# HC32F448 register map
File version: 1.0
CPU: CM4 r0p1, little endian, MPU, FPU, 4 interrupt priority bits
Registers are 32-bit, read-write, reset 0x0 unless marked. A register's access mark holds for its fields unless they carry their own. Offsets are from the block's base; [hi:lo] are bit positions; {n}, {i} and the like mark numbered series.

## TMR41
Base 0x40038000
0x00 OCCRUH 16-bit
0x04 OCCRUL 16-bit
0x08 OCCRVH 16-bit
0x0C OCCRVL 16-bit
0x10 OCCRWH 16-bit
0x14 OCCRWL 16-bit
0x18 OCCRXH 16-bit
0x1C OCCRXL 16-bit
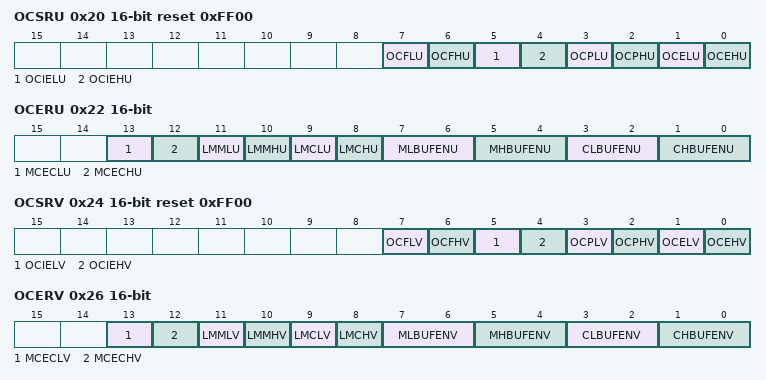
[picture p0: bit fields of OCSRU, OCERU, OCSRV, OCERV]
0x20 OCSRU 16-bit reset 0xFF00
  [7] OCFLU, [6] OCFHU, [5] OCIELU, [4] OCIEHU, [3] OCPLU, [2] OCPHU, [1] OCELU, [0] OCEHU
0x22 OCERU 16-bit
  [13] MCECLU, [12] MCECHU, [11] LMMLU, [10] LMMHU, [9] LMCLU, [8] LMCHU, [7:6] MLBUFENU, [5:4] MHBUFENU, [3:2] CLBUFENU, [1:0] CHBUFENU
0x24 OCSRV 16-bit reset 0xFF00
  [7] OCFLV, [6] OCFHV, [5] OCIELV, [4] OCIEHV, [3] OCPLV, [2] OCPHV, [1] OCELV, [0] OCEHV
0x26 OCERV 16-bit
  [13] MCECLV, [12] MCECHV, [11] LMMLV, [10] LMMHV, [9] LMCLV, [8] LMCHV, [7:6] MLBUFENV, [5:4] MHBUFENV, [3:2] CLBUFENV, [1:0] CHBUFENV
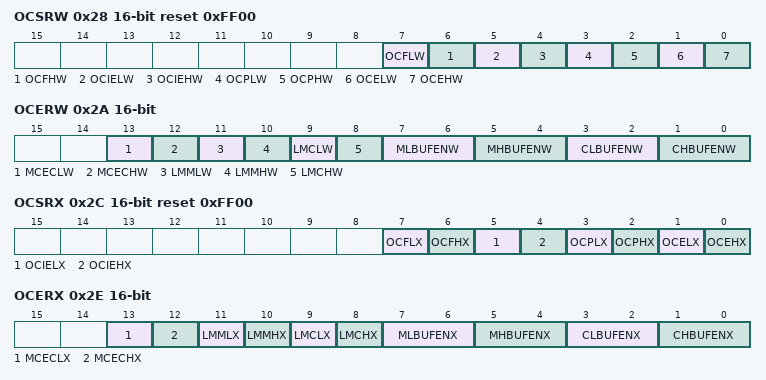
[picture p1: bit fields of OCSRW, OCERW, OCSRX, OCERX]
0x28 OCSRW 16-bit reset 0xFF00
  [7] OCFLW, [6] OCFHW, [5] OCIELW, [4] OCIEHW, [3] OCPLW, [2] OCPHW, [1] OCELW, [0] OCEHW
0x2A OCERW 16-bit
  [13] MCECLW, [12] MCECHW, [11] LMMLW, [10] LMMHW, [9] LMCLW, [8] LMCHW, [7:6] MLBUFENW, [5:4] MHBUFENW, [3:2] CLBUFENW, [1:0] CHBUFENW
0x2C OCSRX 16-bit reset 0xFF00
  [7] OCFLX, [6] OCFHX, [5] OCIELX, [4] OCIEHX, [3] OCPLX, [2] OCPHX, [1] OCELX, [0] OCEHX
0x2E OCERX 16-bit
  [13] MCECLX, [12] MCECHX, [11] LMMLX, [10] LMMHX, [9] LMCLX, [8] LMCHX, [7:6] MLBUFENX, [5:4] MHBUFENX, [3:2] CLBUFENX, [1:0] CHBUFENX
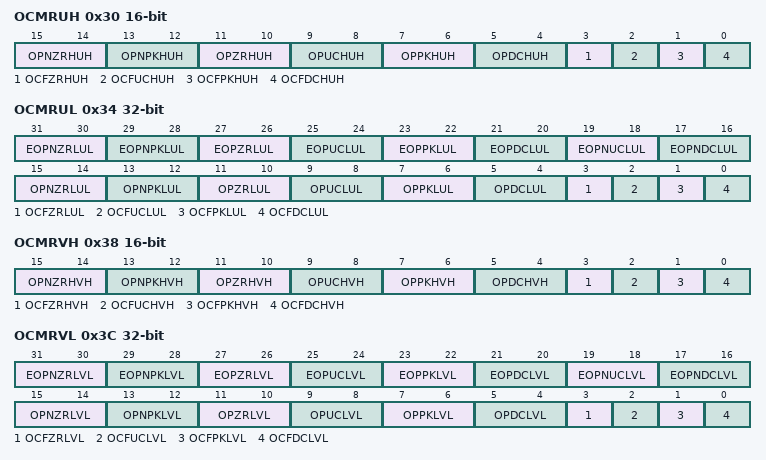
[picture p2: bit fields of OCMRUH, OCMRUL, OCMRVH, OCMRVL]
0x30 OCMRUH 16-bit
  [15:14] OPNZRHUH, [13:12] OPNPKHUH, [11:10] OPZRHUH, [9:8] OPUCHUH, [7:6] OPPKHUH, [5:4] OPDCHUH, [3] OCFZRHUH, [2] OCFUCHUH, [1] OCFPKHUH, [0] OCFDCHUH
0x34 OCMRUL
  [31:30] EOPNZRLUL, [29:28] EOPNPKLUL, [27:26] EOPZRLUL, [25:24] EOPUCLUL, [23:22] EOPPKLUL, [21:20] EOPDCLUL, [19:18] EOPNUCLUL, [17:16] EOPNDCLUL, [15:14] OPNZRLUL, [13:12] OPNPKLUL, [11:10] OPZRLUL, [9:8] OPUCLUL, [7:6] OPPKLUL, [5:4] OPDCLUL, [3] OCFZRLUL, [2] OCFUCLUL, [1] OCFPKLUL, [0] OCFDCLUL
0x38 OCMRVH 16-bit
  [15:14] OPNZRHVH, [13:12] OPNPKHVH, [11:10] OPZRHVH, [9:8] OPUCHVH, [7:6] OPPKHVH, [5:4] OPDCHVH, [3] OCFZRHVH, [2] OCFUCHVH, [1] OCFPKHVH, [0] OCFDCHVH
0x3C OCMRVL
  [31:30] EOPNZRLVL, [29:28] EOPNPKLVL, [27:26] EOPZRLVL, [25:24] EOPUCLVL, [23:22] EOPPKLVL, [21:20] EOPDCLVL, [19:18] EOPNUCLVL, [17:16] EOPNDCLVL, [15:14] OPNZRLVL, [13:12] OPNPKLVL, [11:10] OPZRLVL, [9:8] OPUCLVL, [7:6] OPPKLVL, [5:4] OPDCLVL, [3] OCFZRLVL, [2] OCFUCLVL, [1] OCFPKLVL, [0] OCFDCLVL
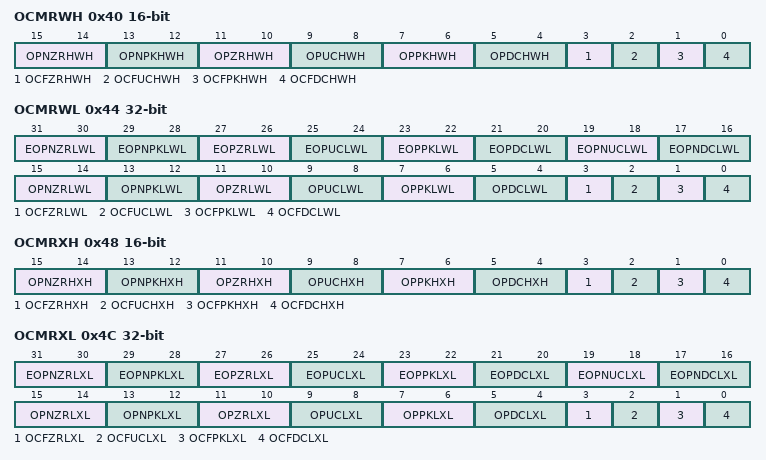
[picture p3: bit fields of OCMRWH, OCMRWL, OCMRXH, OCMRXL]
0x40 OCMRWH 16-bit
  [15:14] OPNZRHWH, [13:12] OPNPKHWH, [11:10] OPZRHWH, [9:8] OPUCHWH, [7:6] OPPKHWH, [5:4] OPDCHWH, [3] OCFZRHWH, [2] OCFUCHWH, [1] OCFPKHWH, [0] OCFDCHWH
0x44 OCMRWL
  [31:30] EOPNZRLWL, [29:28] EOPNPKLWL, [27:26] EOPZRLWL, [25:24] EOPUCLWL, [23:22] EOPPKLWL, [21:20] EOPDCLWL, [19:18] EOPNUCLWL, [17:16] EOPNDCLWL, [15:14] OPNZRLWL, [13:12] OPNPKLWL, [11:10] OPZRLWL, [9:8] OPUCLWL, [7:6] OPPKLWL, [5:4] OPDCLWL, [3] OCFZRLWL, [2] OCFUCLWL, [1] OCFPKLWL, [0] OCFDCLWL
0x48 OCMRXH 16-bit
  [15:14] OPNZRHXH, [13:12] OPNPKHXH, [11:10] OPZRHXH, [9:8] OPUCHXH, [7:6] OPPKHXH, [5:4] OPDCHXH, [3] OCFZRHXH, [2] OCFUCHXH, [1] OCFPKHXH, [0] OCFDCHXH
0x4C OCMRXL
  [31:30] EOPNZRLXL, [29:28] EOPNPKLXL, [27:26] EOPZRLXL, [25:24] EOPUCLXL, [23:22] EOPPKLXL, [21:20] EOPDCLXL, [19:18] EOPNUCLXL, [17:16] EOPNDCLXL, [15:14] OPNZRLXL, [13:12] OPNPKLXL, [11:10] OPZRLXL, [9:8] OPUCLXL, [7:6] OPPKLXL, [5:4] OPDCLXL, [3] OCFZRLXL, [2] OCFUCLXL, [1] OCFPKLXL, [0] OCFDCLXL
0x50 CPSR 16-bit reset 0xFFFF
0x54 CNTR 16-bit
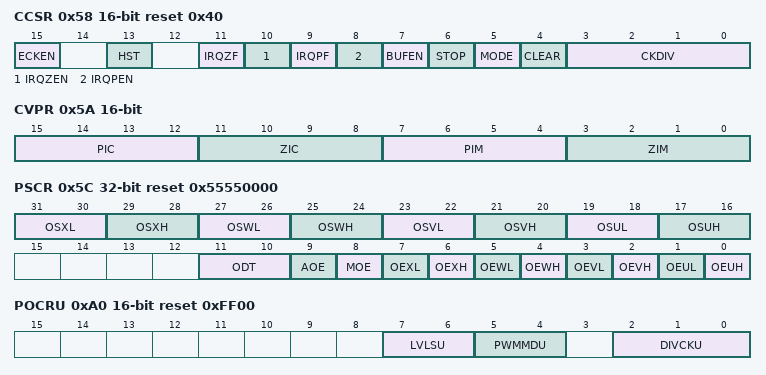
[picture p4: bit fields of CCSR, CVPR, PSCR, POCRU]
0x58 CCSR 16-bit reset 0x40
  [15] ECKEN, [13] HST, [11] IRQZF, [10] IRQZEN, [9] IRQPF, [8] IRQPEN, [7] BUFEN, [6] STOP, [5] MODE, [4] CLEAR, [3:0] CKDIV
0x5A CVPR 16-bit
  [15:12] PIC ro, [11:8] ZIC ro, [7:4] PIM, [3:0] ZIM
0x5C PSCR reset 0x55550000
  [31:30] OSXL, [29:28] OSXH, [27:26] OSWL, [25:24] OSWH, [23:22] OSVL, [21:20] OSVH, [19:18] OSUL, [17:16] OSUH, [11:10] ODT, [9] AOE, [8] MOE, [7] OEXL, [6] OEXH, [5] OEWL, [4] OEWH, [3] OEVL, [2] OEVH, [1] OEUL, [0] OEUH
0x82 PFSRU 16-bit
0x84 PDARU 16-bit
0x86 PDBRU 16-bit
0x8A PFSRV 16-bit
0x8C PDARV 16-bit
0x8E PDBRV 16-bit
0x92 PFSRW 16-bit
0x94 PDARW 16-bit
0x96 PDBRW 16-bit
0x9A PFSRX 16-bit
0x9C PDARX 16-bit
0x9E PDBRX 16-bit
0xA0 POCRU 16-bit reset 0xFF00
  [7:6] LVLSU, [5:4] PWMMDU, [2:0] DIVCKU
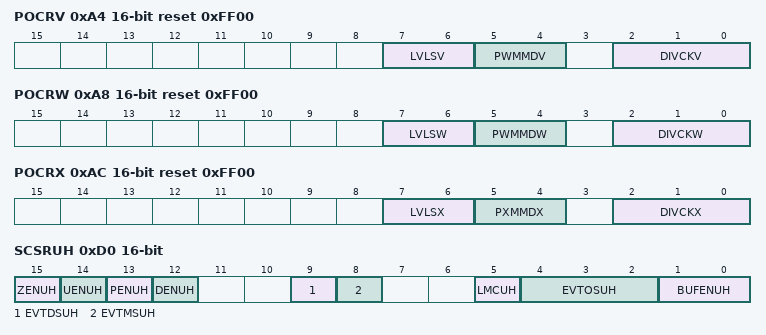
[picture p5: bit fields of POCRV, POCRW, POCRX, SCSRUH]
0xA4 POCRV 16-bit reset 0xFF00
  [7:6] LVLSV, [5:4] PWMMDV, [2:0] DIVCKV
0xA8 POCRW 16-bit reset 0xFF00
  [7:6] LVLSW, [5:4] PWMMDW, [2:0] DIVCKW
0xAC POCRX 16-bit reset 0xFF00
  [7:6] LVLSX, [5:4] PXMMDX, [2:0] DIVCKX
0xB0 SCCRUH 16-bit
0xB4 SCCRUL 16-bit
0xB8 SCCRVH 16-bit
0xBC SCCRVL 16-bit
0xC0 SCCRWH 16-bit
0xC4 SCCRWL 16-bit
0xC8 SCCRXH 16-bit
0xCC SCCRXL 16-bit
0xD0 SCSRUH 16-bit
  [15] ZENUH, [14] UENUH, [13] PENUH, [12] DENUH, [9] EVTDSUH, [8] EVTMSUH, [5] LMCUH, [4:2] EVTOSUH, [1:0] BUFENUH
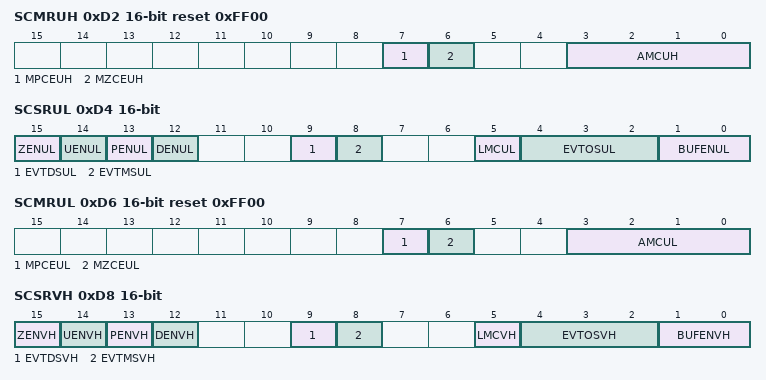
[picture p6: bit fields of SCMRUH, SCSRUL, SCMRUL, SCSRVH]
0xD2 SCMRUH 16-bit reset 0xFF00
  [7] MPCEUH, [6] MZCEUH, [3:0] AMCUH
0xD4 SCSRUL 16-bit
  [15] ZENUL, [14] UENUL, [13] PENUL, [12] DENUL, [9] EVTDSUL, [8] EVTMSUL, [5] LMCUL, [4:2] EVTOSUL, [1:0] BUFENUL
0xD6 SCMRUL 16-bit reset 0xFF00
  [7] MPCEUL, [6] MZCEUL, [3:0] AMCUL
0xD8 SCSRVH 16-bit
  [15] ZENVH, [14] UENVH, [13] PENVH, [12] DENVH, [9] EVTDSVH, [8] EVTMSVH, [5] LMCVH, [4:2] EVTOSVH, [1:0] BUFENVH
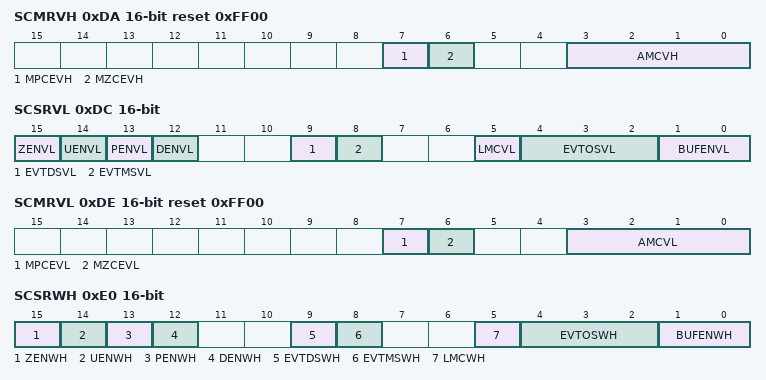
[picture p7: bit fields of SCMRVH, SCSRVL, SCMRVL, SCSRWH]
0xDA SCMRVH 16-bit reset 0xFF00
  [7] MPCEVH, [6] MZCEVH, [3:0] AMCVH
0xDC SCSRVL 16-bit
  [15] ZENVL, [14] UENVL, [13] PENVL, [12] DENVL, [9] EVTDSVL, [8] EVTMSVL, [5] LMCVL, [4:2] EVTOSVL, [1:0] BUFENVL
0xDE SCMRVL 16-bit reset 0xFF00
  [7] MPCEVL, [6] MZCEVL, [3:0] AMCVL
0xE0 SCSRWH 16-bit
  [15] ZENWH, [14] UENWH, [13] PENWH, [12] DENWH, [9] EVTDSWH, [8] EVTMSWH, [5] LMCWH, [4:2] EVTOSWH, [1:0] BUFENWH
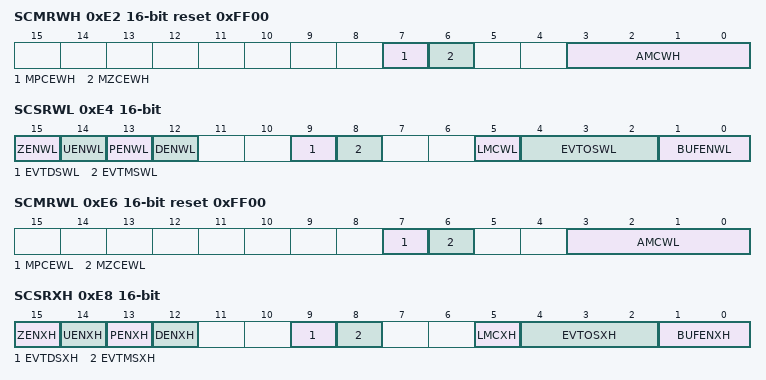
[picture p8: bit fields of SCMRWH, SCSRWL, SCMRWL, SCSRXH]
0xE2 SCMRWH 16-bit reset 0xFF00
  [7] MPCEWH, [6] MZCEWH, [3:0] AMCWH
0xE4 SCSRWL 16-bit
  [15] ZENWL, [14] UENWL, [13] PENWL, [12] DENWL, [9] EVTDSWL, [8] EVTMSWL, [5] LMCWL, [4:2] EVTOSWL, [1:0] BUFENWL
0xE6 SCMRWL 16-bit reset 0xFF00
  [7] MPCEWL, [6] MZCEWL, [3:0] AMCWL
0xE8 SCSRXH 16-bit
  [15] ZENXH, [14] UENXH, [13] PENXH, [12] DENXH, [9] EVTDSXH, [8] EVTMSXH, [5] LMCXH, [4:2] EVTOSXH, [1:0] BUFENXH
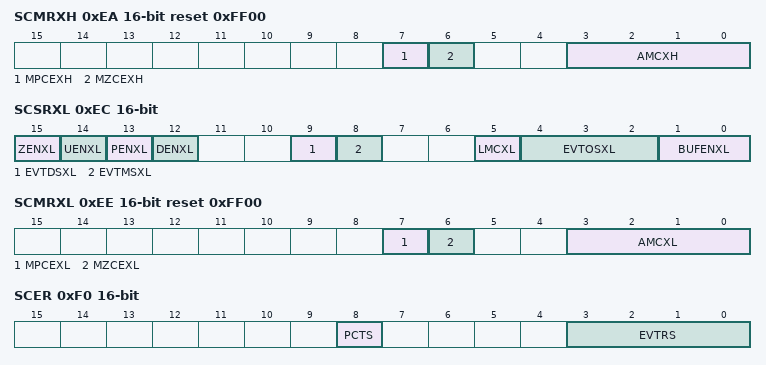
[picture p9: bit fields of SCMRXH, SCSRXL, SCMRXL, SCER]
0xEA SCMRXH 16-bit reset 0xFF00
  [7] MPCEXH, [6] MZCEXH, [3:0] AMCXH
0xEC SCSRXL 16-bit
  [15] ZENXL, [14] UENXL, [13] PENXL, [12] DENXL, [9] EVTDSXL, [8] EVTMSXL, [5] LMCXL, [4:2] EVTOSXL, [1:0] BUFENXL
0xEE SCMRXL 16-bit reset 0xFF00
  [7] MPCEXL, [6] MZCEXL, [3:0] AMCXL
0xF0 SCER 16-bit
  [8] PCTS, [3:0] EVTRS
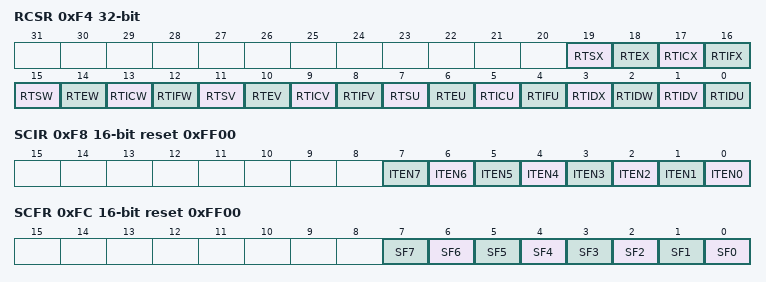
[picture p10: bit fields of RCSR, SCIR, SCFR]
0xF4 RCSR
  [19] RTSX, [18] RTEX, [17] RTICX, [16] RTIFX ro, [15] RTSW, [14] RTEW, [13] RTICW, [12] RTIFW ro, [11] RTSV, [10] RTEV, [9] RTICV, [8] RTIFV ro, [7] RTSU, [6] RTEU, [5] RTICU, [4] RTIFU ro, [3] RTIDX, [2] RTIDW, [1] RTIDV, [0] RTIDU
0xF8 SCIR 16-bit reset 0xFF00
  [n] ITEN{n} (n=0..7)
0xFC SCFR 16-bit reset 0xFF00
  [n] SF{n} (n=0..7)

## TMR42
Base 0x40038400
Same registers: TMR43 0x40038E00
Registers as TMR41; these are added or differ:
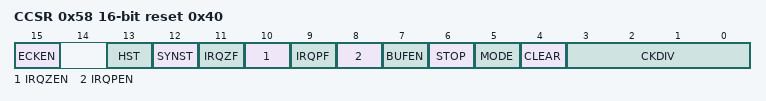
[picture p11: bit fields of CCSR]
0x58 CCSR 16-bit reset 0x40
  [15] ECKEN, [13] HST, [12] SYNST, [11] IRQZF, [10] IRQZEN, [9] IRQPF, [8] IRQPEN, [7] BUFEN, [6] STOP, [5] MODE, [4] CLEAR, [3:0] CKDIV
